# bcm2835_lpa register map
Vendor: BROADCOM; Series: BCM2835; File version: A
CPU: CA72 r0p0, little endian, MPU, FPU, 2 interrupt priority bits
Registers are 32-bit, read-write, reset 0x0 unless marked. A register's access mark holds for its fields unless they carry their own. Offsets are from the block's base; [hi:lo] are bit positions; {n}, {i} and the like mark numbered series; 'fields as' and 'values as' point back to an identical list.

## SPI1 — Aux SPI
Base 0x20215080
Same registers: SPI2 0x202150C0
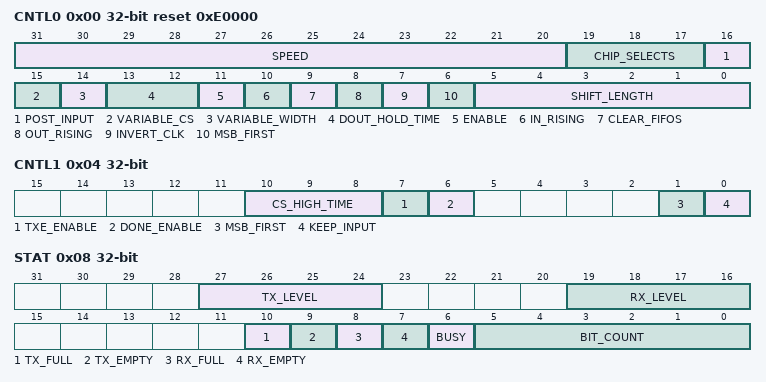
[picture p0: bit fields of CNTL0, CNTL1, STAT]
0x00 CNTL0 reset 0xE0000 — Control 0
  [31:20] SPEED — SPI clock speed. clk = sys / 2 * (SPEED + 1)
  [19:17] CHIP_SELECTS — The CS pattern when active
  [16] POST_INPUT — Post input mode
  [15] VARIABLE_CS — Take CS pattern and data from TX FIFO (along with VARIABLE_WIDTH)
  [14] VARIABLE_WIDTH — Take shift length and data from FIFO
  [13:12] DOUT_HOLD_TIME — Controls extra DOUT hold time in system clock cycles
    0=0; 1=1; 2=4; 3=7
  [11] ENABLE — Enable the interface
  [10] IN_RISING — Data is clocked in on rising edge of CLK
  [9] CLEAR_FIFOS
  [8] OUT_RISING — Data is clocked out on rising edge of CLK
  [7] INVERT_CLK — Idle clock high
  [6] MSB_FIRST — Shift out the most significant bit (MSB) first
  [5:0] SHIFT_LENGTH — Number of bits to shift
0x04 CNTL1 — Control 1
  [10:8] CS_HIGH_TIME — Additional SPI clock cycles where CS is high
  [7] TXE_ENABLE — Enable TX empty interrupt
  [6] DONE_ENABLE — Enable DONE interrupt
  [1] MSB_FIRST — Shift the most significant bit first (MSB)
  [0] KEEP_INPUT — Don't clear the RX shift register before a new transaction
0x08 STAT — Status
  [27:24] TX_LEVEL — Number of entries in TX FIFO
  [19:16] RX_LEVEL — Number of entries in RX FIFO
  [10] TX_FULL — TX FIFO is full
  [9] TX_EMPTY — TX FIFO is empty
  [8] RX_FULL — RX FIFO is full
  [7] RX_EMPTY — RX FIFO is empty
  [6] BUSY — Indicates a transfer is ongoing
  [5:0] BIT_COUNT — Number of bits left to be processed.
0x0C PEEK ro — Read the RXFIFO without removing an entry
  [15:0] DATA — FIFO data access
{0x20+4i} IO{i} (i=0..3) — Writing to the FIFO will deassert CS at the end of the access
  [15:0] DATA — FIFO data access
{0x30+4i} TXHOLD{i} (i=0..3) — Writing to the FIFO will maintain CS at the end of the access
  [15:0] DATA — FIFO data access

## LIC — Broadcom Legacy Interrupt Controller
Base 0x2000B000
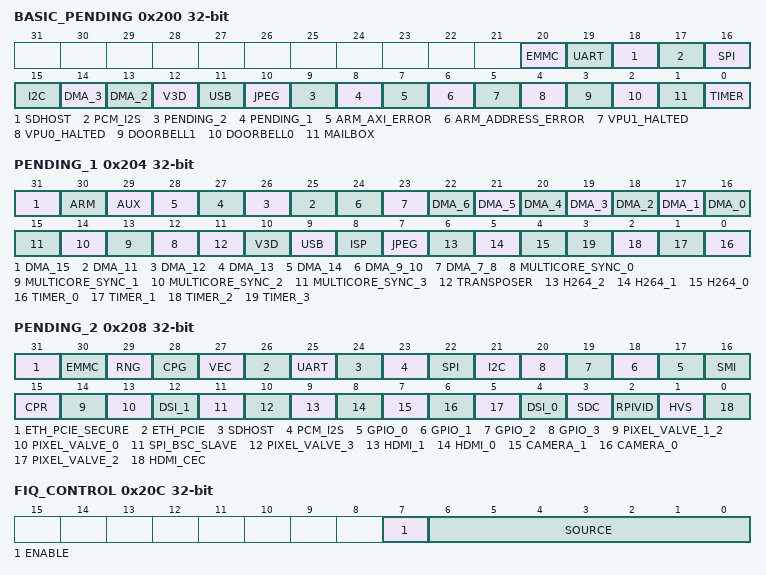
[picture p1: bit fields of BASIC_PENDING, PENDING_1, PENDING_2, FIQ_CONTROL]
0x200 BASIC_PENDING ro — Basic pending info
  [20] EMMC — OR of EMMC and EMMC2
  [19] UART — OR of all PL011 UARTs
  [18] SDHOST
  [17] PCM_I2S
  [16] SPI — OR of all SPI
  [15] I2C — OR of all I2C
  [14] DMA_3
  [13] DMA_2
  [12] V3D
  [11] USB
  [10] JPEG
  [9] PENDING_2 — One or more bits are set in PENDING_2 (ignores 53 - 57, 62)
  [8] PENDING_1 — One or more bits are set in PENDING_1 (ignores 7, 9, 10, 18, 19)
  [7] ARM_AXI_ERROR
  [6] ARM_ADDRESS_ERROR
  [5] VPU1_HALTED
  [4] VPU0_HALTED
  [3] DOORBELL1
  [2] DOORBELL0
  [1] MAILBOX
  [0] TIMER — ARMC Timer
0x204 PENDING_1 ro — Pending state for interrupts 1 - 31
  [31] DMA_15
  [30] ARM
  [29] AUX — OR of UART1, SPI1 and SPI2
  [n+14] DMA_{n} (n=11..14)
  [24] DMA_9_10 — OR of DMA 9 and 10
  [23] DMA_7_8 — OR of DMA 7 and 8
  [n+16] DMA_{n} (n=0..6)
  [n+12] MULTICORE_SYNC_{n} (n=0..3)
  [11] TRANSPOSER
  [10] V3D
  [9] USB
  [8] ISP
  [7] JPEG
  [6] H264_2
  [5] H264_1
  [4] H264_0
  [n] TIMER_{n} (n=0..3)
0x208 PENDING_2 ro — Pending state for interrupts 32 - 63
  [31] ETH_PCIE_SECURE
  [30] EMMC — OR of EMMC and EMMC2
  [29] RNG
  [28] CPG
  [27] VEC
  [26] ETH_PCIE — OR of all ETH_PCIe L2
  [25] UART — OR of all PL011 UARTs
  [24] SDHOST
  [23] PCM_I2S
  [22] SPI — OR of all SPI
  [21] I2C — OR of all I2C
  [n+17] GPIO_{n} (n=0..3)
  [16] SMI
  [15] CPR
  [14] PIXEL_VALVE_1_2 — OR of Pixel Valve 1 and 2
  [13] PIXEL_VALVE_0
  [12] DSI_1
  [11] SPI_BSC_SLAVE
  [10] PIXEL_VALVE_3
  [9] HDMI_1
  [8] HDMI_0
  [7] CAMERA_1
  [6] CAMERA_0
  [5] PIXEL_VALVE_2
  [4] DSI_0
  [3] SDC
  [2] RPIVID
  [1] HVS
  [0] HDMI_CEC
0x20C FIQ_CONTROL
  [7] ENABLE — FIQ Enable
  [6:0] SOURCE — FIQ Source
    {v}=TIMER_{v} (v=0..3); 4=H264_0; 5=H264_1; 6=H264_2; 7=JPEG; 8=ISP; 9=USB; 10=V3D; 11=TRANSPOSER; {v}=MULTICORE_SYNC_{v-12} (v=12..15); {v}=DMA_{v-16} (v=16..22); 23=DMA_7_8 (OR of DMA 7 and 8); 24=DMA_9_10 (OR of DMA 9 and 10); {v}=DMA_{v-14} (v=25..28); 29=AUX (OR of UART1, SPI1 and SPI2); 30=ARM; 31=DMA_15; 32=HDMI_CEC; 33=HVS; 34=RPIVID; 35=SDC; 36=DSI_0; 37=PIXEL_VALVE_2; 38=CAMERA_0; 39=CAMERA_1; 40=HDMI_0; 41=HDMI_1; 42=PIXEL_VALVE_3; 43=SPI_BSC_SLAVE; 44=DSI_1; 45=PIXEL_VALVE_0; 46=PIXEL_VALVE_1_2 (OR of Pixel Valve 1 and 2); 47=CPR; 48=SMI; {v}=GPIO_{v-49} (v=49..52); 53=I2C (OR of all I2C); 54=SPI (OR of all SPI); 55=PCM_I2S; 56=SDHOST; 57=UART (OR of all PL011 UARTs); 58=ETH_PCIE (OR of all ETH_PCIe L2); 59=VEC; 60=CPG; 61=RNG; 62=EMMC (OR of EMMC and EMMC2); 63=ETH_PCIE_SECURE; 64=TIMER (ARMC Timer); 65=MAILBOX; 66=DOORBELL0; 67=DOORBELL1; 68=VPU0_HALTED; 69=VPU1_HALTED; 70=ARM_ADDRESS_ERROR; 71=ARM_AXI_ERROR
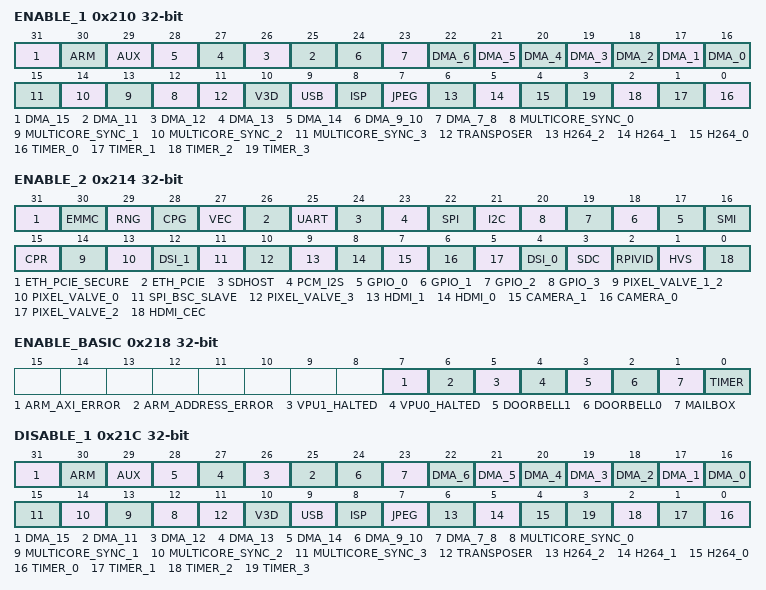
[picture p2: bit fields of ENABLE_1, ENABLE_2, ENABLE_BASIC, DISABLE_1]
0x210 ENABLE_1 write-1-sets — Enable interrupts 1 - 31
  fields as PENDING_1
0x214 ENABLE_2 write-1-sets — Enable interrupts 32 - 63
  fields as PENDING_2
0x218 ENABLE_BASIC write-1-sets — Enable basic interrupts
  [7] ARM_AXI_ERROR
  [6] ARM_ADDRESS_ERROR
  [5] VPU1_HALTED
  [4] VPU0_HALTED
  [3] DOORBELL1
  [2] DOORBELL0
  [1] MAILBOX
  [0] TIMER — ARMC Timer
0x21C DISABLE_1 write-1-clears — Disable interrupts 1 - 31
  fields as PENDING_1
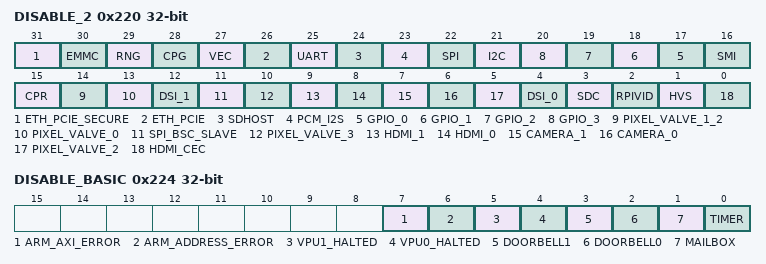
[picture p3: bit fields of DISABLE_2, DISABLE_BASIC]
0x220 DISABLE_2 write-1-clears — Disable interrupts 32 - 63
  fields as PENDING_2
0x224 DISABLE_BASIC write-1-clears — Disable basic interrupts
  fields as ENABLE_BASIC
